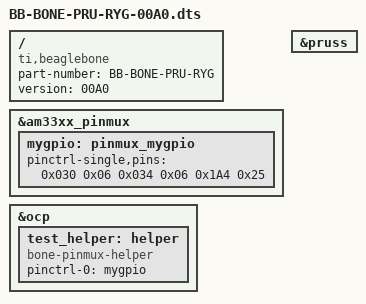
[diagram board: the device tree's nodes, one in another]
/* pru dts file BB-BONE-PRU-RYG-00A0.dts */
/dts-v1/;
/plugin/;

/ {
  compatible = "ti,beaglebone", "ti,beaglebone-black";
 
  /* identification */
  part-number = "BB-BONE-PRU-RYG";
  version = "00A0";
  
  fragment@0 {
    target = <&am33xx_pinmux>;
    __overlay__ {
      mygpio: pinmux_mygpio{
        pinctrl-single,pins = <
          0x030 0x06 /*Red pin8_12 44*/
	        0x034 0x06 /*Yellow pin8_11 45*/	
	        0x1A4 0x25 /*Green pin9_27 115*/
          >;
      };
    };
  };
 
  fragment@1 {
    target = <&ocp>;
    __overlay__ {
      test_helper: helper {
        compatible = "bone-pinmux-helper";
        pinctrl-names = "default";
        pinctrl-0 = <&mygpio>;
        status = "okay";
      };
    };
  };
 
  fragment@2{
  target = <&pruss>;
    __overlay__ {
      status = "okay";
    };
  };
};
